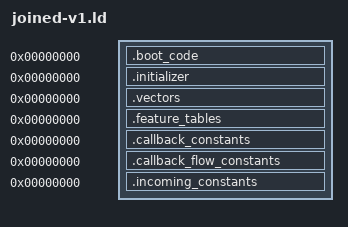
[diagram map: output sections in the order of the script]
OUTPUT_ARCH(riscv)
SECTIONS
{
 .boot_code 0 : SUBALIGN(2) { *(.boot_code)
  *(.text.tsl9_callback_flow_external_92ba)
  *(.text.tsl9_ota_runtime_block_92d8)
  *(.text.tsl9_ota_entry_92f2)
  *(.text.tsl9_ota_runtime_block_92f8)
  *(.text.tsl9_ota_runtime_block_9304)
  *(.text.tsl9_ota_runtime_block_9308)
  *(.text.tsl9_ota_runtime_block_931c)
  *(.text.tsl9_ota_runtime_block_9322)
  *(.text.tsl9_ota_runtime_block_9324)
  *(.text.tsl9_ota_runtime_block_932c)
  *(.text.tsl9_ota_runtime_block_9330)
  *(.text.tsl9_main_runtime_external_9c0a)
  *(.text.tsl9_ota_runtime_block_9c22)
  *(.text.tsl9_ota_runtime_block_9c2a)
  *(.text.tsl9_ota_runtime_block_9c30)
  *(.text.tsl9_ota_runtime_block_9c38)
  *(.text.tsl9_ota_runtime_block_9c3c)
  *(.text.tsl9_ota_entry_9c4a)
  *(.text.tsl9_ota_runtime_block_9c66)
  *(.text.tsl9_ota_runtime_block_9c6a)
  *(.text.tsl9_ota_runtime_block_9c72)
  *(.text.tsl9_ota_runtime_block_9c7a)
  *(.text.tsl9_ota_runtime_block_9c8c)
  *(.text.tsl9_ota_runtime_block_9c94)
  *(.text.tsl9_ota_runtime_block_9c9c)
  *(.text.tsl9_ota_runtime_block_9ca2)
  *(.text.tsl9_ota_runtime_block_9caa)
  *(.text.tsl9_ota_runtime_block_9cd2)
  *(.text.tsl9_ota_runtime_block_9ce0)
  *(.text.tsl9_ota_runtime_block_9cee)
  *(.text.tsl9_ota_runtime_block_9cf4)
  *(.text.tsl9_ota_runtime_block_9d02)
  *(.text.tsl9_ota_runtime_block_9d06)
  *(.text.tsl9_ota_runtime_block_9d0c)
  *(.text.tsl9_ota_runtime_block_9d1c)
  *(.text.tsl9_ota_runtime_block_9d22)
  *(.text.tsl9_ota_runtime_block_9d2a)
  *(.text.tsl9_ota_runtime_block_9d3e)
  *(.text.tsl9_ota_runtime_block_9d40)
  *(.text.tsl9_ota_runtime_block_9d4a)
  *(.text.tsl9_ota_runtime_block_9d5e)
  *(.text.tsl9_ota_runtime_block_9d72)
  *(.text.tsl9_ota_runtime_block_9d78)
  *(.text.tsl9_ota_runtime_block_9d7e)
  *(.text.tsl9_ota_runtime_block_9d80)
  *(.text.tsl9_ota_runtime_block_9d9e)
  *(.text.tsl9_ota_runtime_block_9da0)
  *(.text.tsl9_ota_runtime_block_9da6)
  *(.text.tsl9_ota_runtime_block_9daa)
  *(.text.tsl9_ota_runtime_block_9db2)
  *(.text.tsl9_ota_runtime_block_9db8)
  *(.text.tsl9_ota_runtime_block_9dba)
  *(.text.tsl9_ota_runtime_block_9dc6)
  *(.text.tsl9_ota_runtime_block_9dce)
  *(.text.tsl9_ota_runtime_block_9dd4)
  *(.text.tsl9_ota_runtime_block_9dde)
  *(.text.tsl9_ota_runtime_block_9de2)
  *(.text.tsl9_ota_runtime_block_9df2)
  *(.text.tsl9_ota_runtime_block_9df6)
  *(.text.tsl9_ota_runtime_block_9df8)
  *(.text.tsl9_ota_runtime_block_9e00)
  *(.text.tsl9_ota_runtime_block_9e06)
  *(.text.tsl9_ota_runtime_block_9e0e)
  *(.text.tsl9_ota_runtime_block_9e18)
  *(.text.tsl9_ota_runtime_block_9e1c)
  *(.text.tsl9_ota_runtime_block_9e34)
  *(.text.tsl9_ota_runtime_block_9e48)
  *(.text.tsl9_ota_runtime_block_9e52)
  *(.text.tsl9_incoming_external_13e0e)
  *(.text.tsl9_ota_runtime_block_13e1c)
  *(.text.tsl9_ota_runtime_block_13e22)
  *(.text.tsl9_ota_runtime_block_13e2a)
  *(.text.tsl9_ota_runtime_block_13e2e)
  *(.text.tsl9_ota_runtime_block_13e36)
  *(.text.tsl9_ota_runtime_block_13e3a)
  *(.text.tsl9_ota_runtime_block_13e46)
  *(.text.tsl9_ota_runtime_block_13e4e)
  *(.text.tsl9_ota_runtime_block_13e50)
  *(.text.tsl9_ota_runtime_block_13e58)
  *(.text.tsl9_ota_runtime_block_13e5e)
  *(.text.tsl9_ota_runtime_block_13e62)
  *(.text.tsl9_ota_runtime_block_13e68)
  *(.text.tsl9_ota_runtime_block_13e70)
  *(.text.tsl9_ota_runtime_block_13e72)
  *(.text.tsl9_ota_runtime_block_13e7c)
  *(.text.tsl9_ota_runtime_block_13e80)
  *(.text.tsl9_ota_runtime_block_13e82)
  *(.text.tsl9_ota_runtime_block_13e8a)
  *(.text.tsl9_ota_runtime_block_13e8c)
  *(.text.tsl9_ota_flash_entry_18e90)
  *(.text.tsl9_ota_flash_entry_18e98)
  *(.text.tsl9_ota_flash_entry_18eb6)
  *(.text.tsl9_ota_flash_entry_18ec4)
  *(.text.tsl9_ota_runtime_block_18ee0)
  *(.text.tsl9_ota_runtime_block_18ee6)
  *(.text.tsl9_ota_flash_entry_18ef2)
  *(.text.tsl9_ota_runtime_block_18f02)
  *(.text.tsl9_ota_runtime_block_18f08)
  *(.text.tsl9_ota_runtime_block_18f0c)
  *(.text.tsl9_ota_runtime_block_18f12)
  *(.text.tsl9_ota_runtime_block_18f1a)
  *(.text.tsl9_ota_runtime_block_18f2a)
  *(.text.tsl9_ota_runtime_block_18f30)
  *(.text.tsl9_ota_runtime_block_18f36)
  *(.text.tsl9_ota_runtime_block_18f44)
  *(.text.tsl9_ota_runtime_block_18f4a)
 }
 .initializer 0 : SUBALIGN(4) { *(.initializer) }
 .vectors 0 : SUBALIGN(4) { *(.vectors) }
 .feature_tables 0 : SUBALIGN(4) { *(.feature_tables) }
 .callback_constants 0 : SUBALIGN(4) { *(.callback_constants) }
 .callback_flow_constants 0 : SUBALIGN(4) { *(.callback_flow_constants) }
 .incoming_constants 0 : ALIGN(4) { *(.incoming_constants) }
 /DISCARD/ : { *(.comment) *(.riscv.attributes) *(.llvm_addrsig) }
}
